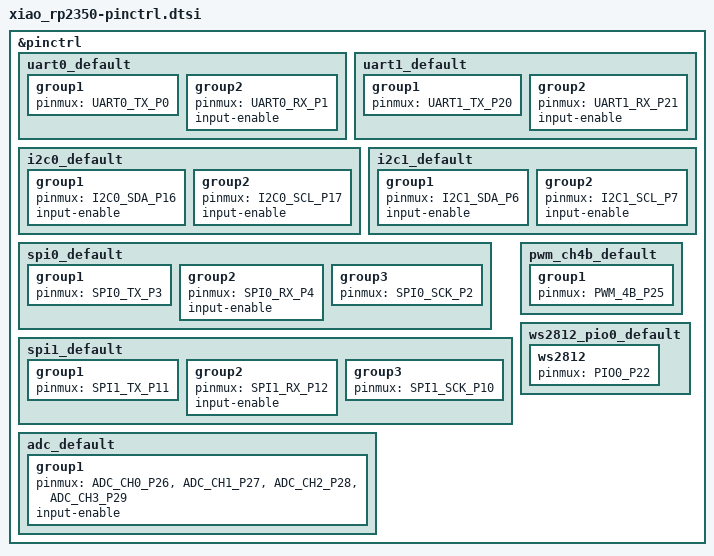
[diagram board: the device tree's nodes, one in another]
/*
 * SPDX-FileCopyrightText: Copyright (c) 2026 Navimatix GmbH
 * SPDX-FileCopyrightText: Copyright (c) 2026 TiaC Systems
 * SPDX-License-Identifier: Apache-2.0
 */

#include <zephyr/dt-bindings/pinctrl/rpi-pico-rp2350a-pinctrl.h>

&pinctrl {
	uart0_default: uart0_default {
		group1 {
			pinmux = <UART0_TX_P0>;
		};

		group2 {
			pinmux = <UART0_RX_P1>;
			input-enable;
		};
	};

	uart1_default: uart1_default {
		group1 {
			pinmux = <UART1_TX_P20>;
		};

		group2 {
			pinmux = <UART1_RX_P21>;
			input-enable;
		};
	};

	i2c0_default: i2c0_default {
		group1 {
			pinmux = <I2C0_SDA_P16>;
			input-enable;
		};

		group2 {
			pinmux = <I2C0_SCL_P17>;
			input-enable;
		};
	};

	i2c1_default: i2c1_default {
		group1 {
			pinmux = <I2C1_SDA_P6>;
			input-enable;
		};

		group2 {
			pinmux = <I2C1_SCL_P7>;
			input-enable;
		};
	};

	spi0_default: spi0_default {
		group1 {
			pinmux = <SPI0_TX_P3>;
		};

		group2 {
			pinmux = <SPI0_RX_P4>;
			input-enable;
		};

		group3 {
			pinmux = <SPI0_SCK_P2>;
		};
	};

	spi1_default: spi1_default {
		group1 {
			pinmux = <SPI1_TX_P11>;
		};

		group2 {
			pinmux = <SPI1_RX_P12>;
			input-enable;
		};

		group3 {
			pinmux = <SPI1_SCK_P10>;
		};
	};

	pwm_ch4b_default: pwm_ch4b_default {
		group1 {
			pinmux = <PWM_4B_P25>;
		};
	};

	adc_default: adc_default {
		group1 {
			pinmux = <ADC_CH0_P26>,
				 <ADC_CH1_P27>,
				 <ADC_CH2_P28>,
				 <ADC_CH3_P29>;
			input-enable;
		};
	};

	ws2812_pio0_default: ws2812_pio0_default {
		ws2812 {
			pinmux = <PIO0_P22>;
		};
	};
};
